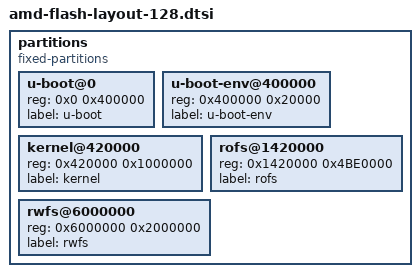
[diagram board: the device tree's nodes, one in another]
// SPDX-License-Identifier: GPL-2.0+
// AST2700 128MB NOR — must match OpenBMC meta-amd/meta-sp7/conf/machine/sp7.conf
// (FLASH_*_OFFSET KB). Do not revert to 2MB u-boot / 0x1220000 rofs (breaks initramfs).
// After DTS cherry-picks: scripts/check-amd-sp7-flash-layout.sh

partitions {
	compatible = "fixed-partitions";
	#address-cells = <1>;
	#size-cells = <1>;

	u-boot@0 {
		reg = <0x0 0x400000>; // 4MB
		label = "u-boot";
	};

	u-boot-env@400000 {
		reg = <0x400000 0x20000>; // 128KB
		label = "u-boot-env";
	};

	kernel@420000 {
		reg = <0x420000 0x1000000>; // 16MB
		label = "kernel";
	};

	rofs@1420000 {
		reg = <0x1420000 0x4BE0000>; // 75.875MB
		label = "rofs";
	};

	rwfs@6000000 {
		reg = <0x6000000 0x2000000>; // 32MB
		label = "rwfs";
	};
};
